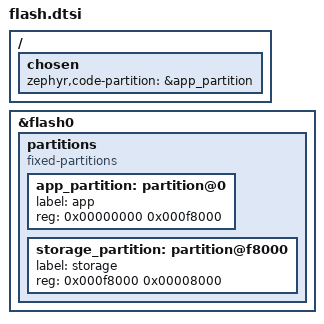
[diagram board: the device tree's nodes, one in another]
&flash0 {
    partitions {
        compatible = "fixed-partitions";
        #address-cells = <1>;
        #size-cells = <1>;

        app_partition: partition@0 {
            label = "app";
            reg = <0x00000000 0x000f8000>;
        };

        storage_partition: partition@f8000 {
            label = "storage";
            reg = <0x000f8000 0x00008000>;
        };
    };
};

/ {
    chosen {
        zephyr,code-partition = &app_partition;
    };
};
